AUTOSAR XML (schema 4-0-3)
standard types defined: Boolean, UInt16, UInt32
package /AUTOSAR_Platform/DataConstrs
  range DC_Boolean: raw 0..1
  range DC_UInt16: raw 0..65535
package /PATAC/Facility/DataTypes/Implementation
  compu method COMPU_Boolean: 0=FALSE, 1=TRUE
  unit NoUnit: factor-si-to-unit=1, offset-si-to-unit=0
package /PATAC/MSM/ComponentTypes
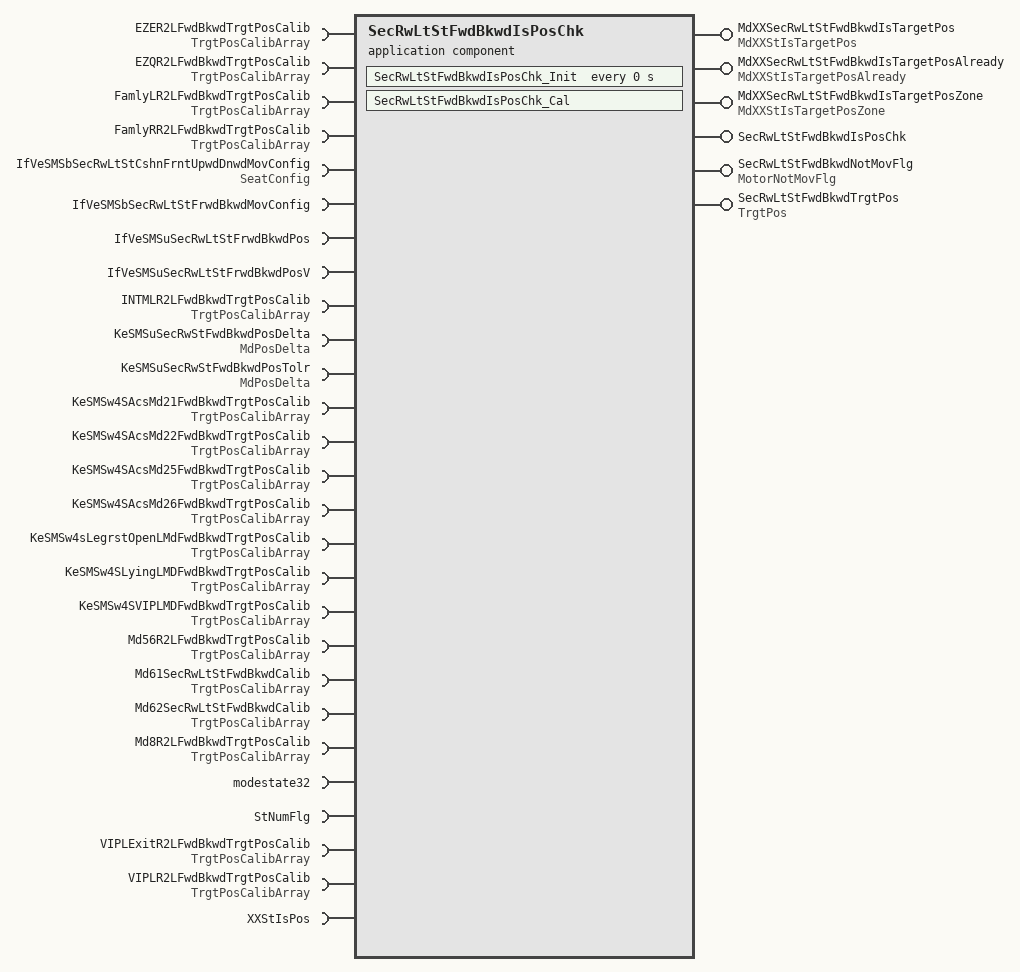
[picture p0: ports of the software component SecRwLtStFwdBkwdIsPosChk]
  application sw component type SecRwLtStFwdBkwdIsPosChk
    6 x provide port:
      MdXXSecRwLtStFwdBkwdIsTargetPos: nonqueued-sender-com-spec{data-element=MdXXStIsTargetPos/Val, init-value=0}, provided-interface=MdXXStIsTargetPos
      MdXXSecRwLtStFwdBkwdIsTargetPosAlready: nonqueued-sender-com-spec{data-element=MdXXStIsTargetPosAlready/Val, init-value=0}, provided-interface=MdXXStIsTargetPosAlready
      MdXXSecRwLtStFwdBkwdIsTargetPosZone: nonqueued-sender-com-spec{data-element=MdXXStIsTargetPosZone/Val, init-value=0}, provided-interface=MdXXStIsTargetPosZone
      SecRwLtStFwdBkwdIsPosChk: server-com-spec{operation=Cal, queue-length=1}, provided-interface=SecRwLtStFwdBkwdIsPosChk
      SecRwLtStFwdBkwdNotMovFlg: nonqueued-sender-com-spec{data-element=MotorNotMovFlg/Val, init-value=0}, provided-interface=MotorNotMovFlg
      SecRwLtStFwdBkwdTrgtPos: nonqueued-sender-com-spec{data-element=TrgtPos/Val, init-value=4095}, provided-interface=TrgtPos
    27 x require port:
      EZER2LFwdBkwdTrgtPosCalib: nonqueued-receiver-com-spec{data-element=TrgtPosArray, filter=data-filter-type=ALWAYS, init-value=[4095, 4095, 4095]}, required-interface=TrgtPosCalibArray
      EZQR2LFwdBkwdTrgtPosCalib: nonqueued-receiver-com-spec{data-element=TrgtPosArray, filter=data-filter-type=ALWAYS, init-value=[4095, 4095, 4095]}, required-interface=TrgtPosCalibArray
      FamlyLR2LFwdBkwdTrgtPosCalib: nonqueued-receiver-com-spec{data-element=TrgtPosArray, filter=data-filter-type=ALWAYS, init-value=[4095, 4095, 4095]}, required-interface=TrgtPosCalibArray
      FamlyRR2LFwdBkwdTrgtPosCalib: nonqueued-receiver-com-spec{data-element=TrgtPosArray, filter=data-filter-type=ALWAYS, init-value=[4095, 4095, 4095]}, required-interface=TrgtPosCalibArray
      IfVeSMSbSecRwLtStCshnFrntUpwdDnwdMovConfig: nonqueued-receiver-com-spec{data-element=SeatConfig/Val, filter=data-filter-type=ALWAYS, init-value=0}, required-interface=SeatConfig
      IfVeSMSbSecRwLtStFrwdBkwdMovConfig: nonqueued-receiver-com-spec{data-element=IfVeSMSbSecRwLtStFrwdBkwdMovConfig/Val, filter=data-filter-type=ALWAYS, init-value=0}, required-interface=IfVeSMSbSecRwLtStFrwdBkwdMovConfig
      IfVeSMSuSecRwLtStFrwdBkwdPos: nonqueued-receiver-com-spec{data-element=IfVeSMSuSecRwLtStFrwdBkwdPos/Val, filter=data-filter-type=ALWAYS, init-value=0}, required-interface=IfVeSMSuSecRwLtStFrwdBkwdPos
      IfVeSMSuSecRwLtStFrwdBkwdPosV: nonqueued-receiver-com-spec{data-element=IfVeSMSuSecRwLtStFrwdBkwdPosV/Val, filter=data-filter-type=ALWAYS, init-value=0}, required-interface=IfVeSMSuSecRwLtStFrwdBkwdPosV
      INTMLR2LFwdBkwdTrgtPosCalib: nonqueued-receiver-com-spec{data-element=TrgtPosArray, filter=data-filter-type=ALWAYS, init-value=[4095, 4095, 4095]}, required-interface=TrgtPosCalibArray
      KeSMSuSecRwStFwdBkwdPosDelta: parameter-require-com-spec{init-value=KeSMSuSecRwStFwdBkwdPosDelta_Val:300, parameter=Val}, required-interface=MdPosDelta
      KeSMSuSecRwStFwdBkwdPosTolr: parameter-require-com-spec{init-value=KeSMSuSecRwStFwdBkwdPosTolr_Val:300, parameter=Val}, required-interface=MdPosDelta
      KeSMSw4SAcsMd21FwdBkwdTrgtPosCalib: nonqueued-receiver-com-spec{data-element=TrgtPosArray, filter=data-filter-type=ALWAYS, init-value=[4095, 4095, 4095]}, required-interface=TrgtPosCalibArray
      KeSMSw4SAcsMd22FwdBkwdTrgtPosCalib: nonqueued-receiver-com-spec{data-element=TrgtPosArray, filter=data-filter-type=ALWAYS, init-value=[4095, 4095, 4095]}, required-interface=TrgtPosCalibArray
      KeSMSw4SAcsMd25FwdBkwdTrgtPosCalib: nonqueued-receiver-com-spec{data-element=TrgtPosArray, filter=data-filter-type=ALWAYS, init-value=[4095, 4095, 4095]}, required-interface=TrgtPosCalibArray
      KeSMSw4SAcsMd26FwdBkwdTrgtPosCalib: nonqueued-receiver-com-spec{data-element=TrgtPosArray, filter=data-filter-type=ALWAYS, init-value=[4095, 4095, 4095]}, required-interface=TrgtPosCalibArray
      KeSMSw4sLegrstOpenLMdFwdBkwdTrgtPosCalib: nonqueued-receiver-com-spec{data-element=TrgtPosArray, filter=data-filter-type=ALWAYS, init-value=[4095, 4095, 4095]}, required-interface=TrgtPosCalibArray
      KeSMSw4SLyingLMDFwdBkwdTrgtPosCalib: nonqueued-receiver-com-spec{data-element=TrgtPosArray, filter=data-filter-type=ALWAYS, init-value=[4095, 4095, 4095]}, required-interface=TrgtPosCalibArray
      KeSMSw4SVIPLMDFwdBkwdTrgtPosCalib: nonqueued-receiver-com-spec{data-element=TrgtPosArray, filter=data-filter-type=ALWAYS, init-value=[4095, 4095, 4095]}, required-interface=TrgtPosCalibArray
      Md56R2LFwdBkwdTrgtPosCalib: nonqueued-receiver-com-spec{data-element=TrgtPosArray, filter=data-filter-type=ALWAYS, init-value=[4095, 4095, 4095]}, required-interface=TrgtPosCalibArray
      Md61SecRwLtStFwdBkwdCalib: nonqueued-receiver-com-spec{data-element=TrgtPosArray, filter=data-filter-type=ALWAYS, init-value=[4095, 4095, 4095]}, required-interface=TrgtPosCalibArray
      Md62SecRwLtStFwdBkwdCalib: nonqueued-receiver-com-spec{data-element=TrgtPosArray, filter=data-filter-type=ALWAYS, init-value=[4095, 4095, 4095]}, required-interface=TrgtPosCalibArray
      Md8R2LFwdBkwdTrgtPosCalib: nonqueued-receiver-com-spec{data-element=TrgtPosArray, filter=data-filter-type=ALWAYS, init-value=[4095, 4095, 4095]}, required-interface=TrgtPosCalibArray
      modestate32: nonqueued-receiver-com-spec{data-element=modestate32/Val, filter=data-filter-type=ALWAYS, init-value=0}, required-interface=modestate32
      StNumFlg: required-interface=StNumFlg
        required-com-specs:
          data-element=Is4s, filter=data-filter-type=ALWAYS, init-value=0
          data-element=Is6s, filter=data-filter-type=ALWAYS, init-value=0
          data-element=Is6s7s, filter=data-filter-type=ALWAYS, init-value=0
          data-element=Is7s, filter=data-filter-type=ALWAYS, init-value=0
      VIPLExitR2LFwdBkwdTrgtPosCalib: nonqueued-receiver-com-spec{data-element=TrgtPosArray, filter=data-filter-type=ALWAYS, init-value=[4095, 4095, 4095]}, required-interface=TrgtPosCalibArray
      VIPLR2LFwdBkwdTrgtPosCalib: nonqueued-receiver-com-spec{data-element=TrgtPosArray, filter=data-filter-type=ALWAYS, init-value=[4095, 4095, 4095]}, required-interface=TrgtPosCalibArray
      XXStIsPos: client-com-spec=Get, required-interface=XXStIsPos
    behavior SecRwLtStFwdBkwdIsPosChk_InternalBehavior
      operation invoked event OIT_SecRwLtStFwdBkwdIsPosChk_Cal_SecRwLtStFwdBkwdIsPosChk_Cal: start-on-event=SecRwLtStFwdBkwdIsPosChk_Cal, operation=SecRwLtStFwdBkwdIsPosChk.Cal
      timing event SecRwLtStFwdBkwdIsPosChk_InitEvent: start-on-event=SecRwLtStFwdBkwdIsPosChk_Init, period=0
      runnable SecRwLtStFwdBkwdIsPosChk_Cal
        data-receive-point-by-arguments:
          27 x access:
            IN_EZER2LFwdBkwdTrgtPosCalib_TrgtPosArray: accessed-variable=EZER2LFwdBkwdTrgtPosCalib.TrgtPosArray
            IN_EZQR2LFwdBkwdTrgtPosCalib_TrgtPosArray: accessed-variable=EZQR2LFwdBkwdTrgtPosCalib.TrgtPosArray
            IN_FamlyLR2LFwdBkwdTrgtPosCalib_TrgtPosArray: accessed-variable=FamlyLR2LFwdBkwdTrgtPosCalib.TrgtPosArray
            IN_FamlyRR2LFwdBkwdTrgtPosCalib_TrgtPosArray: accessed-variable=FamlyRR2LFwdBkwdTrgtPosCalib.TrgtPosArray
            IN_IfVeSMSbSecRwLtStFrwdBkwdMovConfig_Val: accessed-variable=IfVeSMSbSecRwLtStFrwdBkwdMovConfig.Val
            IN_IfVeSMSuSecRwLtStFrwdBkwdPos_Val: accessed-variable=IfVeSMSuSecRwLtStFrwdBkwdPos.Val
            IN_IfVeSMSuSecRwLtStFrwdBkwdPosV_Val: accessed-variable=IfVeSMSuSecRwLtStFrwdBkwdPosV.Val
            IN_INTMLR2LFwdBkwdTrgtPosCalib_TrgtPosArray: accessed-variable=INTMLR2LFwdBkwdTrgtPosCalib.TrgtPosArray
            IN_KeSMSw4SAcsMd21FwdBkwdTrgtPosCalib_TrgtPosArray: accessed-variable=KeSMSw4SAcsMd21FwdBkwdTrgtPosCalib.TrgtPosArray
            IN_KeSMSw4SAcsMd22FwdBkwdTrgtPosCalib_TrgtPosArray: accessed-variable=KeSMSw4SAcsMd22FwdBkwdTrgtPosCalib.TrgtPosArray
            IN_KeSMSw4SAcsMd25FwdBkwdTrgtPosCalib_TrgtPosArray: accessed-variable=KeSMSw4SAcsMd25FwdBkwdTrgtPosCalib.TrgtPosArray
            IN_KeSMSw4SAcsMd26FwdBkwdTrgtPosCalib_TrgtPosArray: accessed-variable=KeSMSw4SAcsMd26FwdBkwdTrgtPosCalib.TrgtPosArray
            IN_modestate32_Val: accessed-variable=modestate32.Val
            IN_StNumFlg_Is4s: accessed-variable=StNumFlg.Is4s
            IN_VIPLR2LFwdBkwdTrgtPosCalib_TrgtPosArray: accessed-variable=VIPLR2LFwdBkwdTrgtPosCalib.TrgtPosArray
            REC_IfVeSMSbSecRwLtStCshnFrntUpwdDnwdMovConfig_Val: accessed-variable=IfVeSMSbSecRwLtStCshnFrntUpwdDnwdMovConfig.Val
            REC_KeSMSw4sLegrstOpenLMdFwdBkwdTrgtPosCalib_TrgtPosArray: accessed-variable=KeSMSw4sLegrstOpenLMdFwdBkwdTrgtPosCalib.TrgtPosArray
            REC_KeSMSw4SLyingLMDFwdBkwdTrgtPosCalib_TrgtPosArray: accessed-variable=KeSMSw4SLyingLMDFwdBkwdTrgtPosCalib.TrgtPosArray
            REC_KeSMSw4SVIPLMDFwdBkwdTrgtPosCalib_TrgtPosArray: accessed-variable=KeSMSw4SVIPLMDFwdBkwdTrgtPosCalib.TrgtPosArray
            REC_Md56R2LFwdBkwdTrgtPosCalib_TrgtPosArray: accessed-variable=Md56R2LFwdBkwdTrgtPosCalib.TrgtPosArray
            REC_Md61SecRwLtStFwdBkwdCalib_TrgtPosArray: accessed-variable=Md61SecRwLtStFwdBkwdCalib.TrgtPosArray
            REC_Md62SecRwLtStFwdBkwdCalib_TrgtPosArray: accessed-variable=Md62SecRwLtStFwdBkwdCalib.TrgtPosArray
            REC_Md8R2LFwdBkwdTrgtPosCalib_TrgtPosArray: accessed-variable=Md8R2LFwdBkwdTrgtPosCalib.TrgtPosArray
            REC_StNumFlg_Is6s: accessed-variable=StNumFlg.Is6s
            REC_StNumFlg_Is6s7s: accessed-variable=StNumFlg.Is6s7s
            REC_StNumFlg_Is7s: accessed-variable=StNumFlg.Is7s
            REC_VIPLExitR2LFwdBkwdTrgtPosCalib_TrgtPosArray: accessed-variable=VIPLExitR2LFwdBkwdTrgtPosCalib.TrgtPosArray
        data-send-points:
          5 x access:
            OUT_MdXXSecRwLtStFwdBkwdIsTargetPos_Val: accessed-variable=MdXXSecRwLtStFwdBkwdIsTargetPos.Val
            OUT_MdXXSecRwLtStFwdBkwdIsTargetPosAlready_Val: accessed-variable=MdXXSecRwLtStFwdBkwdIsTargetPosAlready.Val
            OUT_MdXXSecRwLtStFwdBkwdIsTargetPosZone_Val: accessed-variable=MdXXSecRwLtStFwdBkwdIsTargetPosZone.Val
            OUT_SecRwLtStFwdBkwdNotMovFlg_Val: accessed-variable=SecRwLtStFwdBkwdNotMovFlg.Val
            OUT_SecRwLtStFwdBkwdTrgtPos_Val: accessed-variable=SecRwLtStFwdBkwdTrgtPos.Val
        parameter access PA_KeSMSuSecRwStFwdBkwdPosDelta_Val: accessed-parameter=KeSMSuSecRwStFwdBkwdPosDelta.Val
        parameter access PA_KeSMSuSecRwStFwdBkwdPosTolr_Val: accessed-parameter=KeSMSuSecRwStFwdBkwdPosTolr.Val
        sync call SC_XXStIsPos_Get: operation=XXStIsPos.Get, timeout=0
      runnable SecRwLtStFwdBkwdIsPosChk_Init
        parameter access PA_KeSMSuSecRwStFwdBkwdPosDelta_Val: accessed-parameter=KeSMSuSecRwStFwdBkwdPosDelta.Val
        parameter access PA_KeSMSuSecRwStFwdBkwdPosTolr_Val: accessed-parameter=KeSMSuSecRwStFwdBkwdPosTolr.Val
  swc implementation SecRwLtStFwdBkwdIsPosChk_Implementation: behavior=SecRwLtStFwdBkwdIsPosChk_InternalBehavior
    code-descriptors:
      code Default: artifact-descriptors=autosar-engineering-object={short-label=Default, category=SWSRC}
package /PATAC/MSM/ModeAdjust/CalPortInterface
  parameter interface MdPosDelta
    parameter data prototype Val: sw-calibration-access=READ-WRITE, type=UInt16
package /PATAC/MSM/ModeAdjust/DataType
  impl type TrgtPosCalibArray: category=ARRAY, sw-calibration-access=READ-ONLY, type-emitter=RTE  # 0:pos 1:max 2:min
    element Element: array-size=3, array-size-semantics=FIXED-SIZE, implementation-data-type=UInt16, invalid-value=0
package /PATAC/MSM/ModeAdjust/Interfaces
  sender receiver interface IfVeSMSuSecRwLtStFrwdBkwdPosV: invalidation-policy{data-element=IfVeSMSuSecRwLtStFrwdBkwdPosV/Val, handle-invalid=DONT-INVALIDATE}
    data Val: type=Implementation/Boolean
package /PATAC/MSM/ModeAdjust/PortInterface
  client server interface SecRwLtStFwdBkwdIsPosChk
    operation Cal
  client server interface XXStIsPos
    operation Get
      8 x arg, all with server-argument-impl-policy=USE-ARGUMENT-TYPE:
        PosV: type=DataTypes/Boolean, direction=IN
        Pos: type=UInt16, direction=IN
        CalibArray: type=TrgtPosCalibArray, direction=IN
        Delta: type=UInt16, direction=IN
        Tolr: type=UInt16, direction=IN
        IsPos: type=DataTypes/Boolean, direction=OUT
        IsPosZone: type=DataTypes/Boolean, direction=OUT
        IsPosAlready: type=DataTypes/Boolean, direction=OUT
  7 x sender receiver interface:
    MdXXStIsTargetPos: invalidation-policy{data-element=MdXXStIsTargetPos/Val, handle-invalid=DONT-INVALIDATE}
      data Val: type=UInt32
    MdXXStIsTargetPosAlready: invalidation-policy{data-element=MdXXStIsTargetPosAlready/Val, handle-invalid=DONT-INVALIDATE}
      data Val: type=UInt32
    MdXXStIsTargetPosZone: invalidation-policy{data-element=MdXXStIsTargetPosZone/Val, handle-invalid=DONT-INVALIDATE}
      data Val: type=UInt32
    modestate32: invalidation-policy{data-element=modestate32/Val, handle-invalid=DONT-INVALIDATE}
      data Val: type=UInt32
    MotorNotMovFlg: invalidation-policy{data-element=MotorNotMovFlg/Val, handle-invalid=DONT-INVALIDATE}
      data Val: type=Implementation/Boolean
    StNumFlg
      4 x data, all with type=Implementation/Boolean:
        Is4s
        Is6s
        Is6s7s
        Is7s
      invalidation-policys:
        data-element=Is4s, handle-invalid=DONT-INVALIDATE
        data-element=Is6s, handle-invalid=DONT-INVALIDATE
        data-element=Is6s7s, handle-invalid=DONT-INVALIDATE
        data-element=Is7s, handle-invalid=DONT-INVALIDATE
    TrgtPosCalibArray: invalidation-policy{data-element=TrgtPosArray, handle-invalid=DONT-INVALIDATE}
      data TrgtPosArray: type=TrgtPosCalibArray  # 0:Pos 1:Max 2:Min
package /PATAC/MSM/PortInterfaces
  4 x sender receiver interface:
    IfVeSMSbSecRwLtStFrwdBkwdMovConfig: invalidation-policy{data-element=IfVeSMSbSecRwLtStFrwdBkwdMovConfig/Val, handle-invalid=DONT-INVALIDATE}
      data Val: type=Implementation/Boolean
    IfVeSMSuSecRwLtStFrwdBkwdPos: invalidation-policy{data-element=IfVeSMSuSecRwLtStFrwdBkwdPos/Val, handle-invalid=DONT-INVALIDATE}
      data Val: type=UInt16
    SeatConfig: invalidation-policy{data-element=SeatConfig/Val, handle-invalid=DONT-INVALIDATE}
      data Val: type=Implementation/Boolean
    TrgtPos: invalidation-policy{data-element=TrgtPos/Val, handle-invalid=DONT-INVALIDATE}
      data Val: type=UInt16
